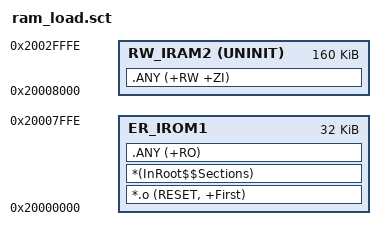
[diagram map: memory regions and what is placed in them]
; *************************************************************
; *** Scatter-Loading Description File generated by uVision ***
; *************************************************************

LR_IROM1 0x20000000 0x00007FFF  {    ; load region size_region
  ER_IROM1 0x20000000 0x00007FFF  {  ; load address = execution address
   *.o (RESET, +First)
   *(InRoot$$Sections)
   .ANY (+RO)
  }
  RW_IRAM2 0x20008000 UNINIT 0x00027FFF  {  ; RW data
   .ANY (+RW +ZI)
  }
}

;ARM_LIB_HEAP 0xD0000000 0x800000 {
;  RW_HEAP 0xD0000000 UNINIT 0x800000  {
;   .ANY (HEAP)
;  }
;}
